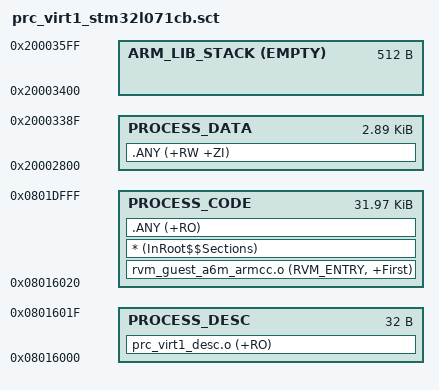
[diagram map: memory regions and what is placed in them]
;******************************************************************************
;Filename    : proc_virt1_stm32l071cb.sct
;Author      : The RVM project generator.
;Date        : 08/08/2024 16:25:18
;Licence     : Unlicense; see COPYING for details.
;Description : The scatter file for ARMv7-M layout. This file is intended
;              to be used with STM32L071CB.
;******************************************************************************

;Descriptor *******************************************************************
DESC 0x8016000 0x20
{
    ;Process header segment
    PROCESS_DESC 0x8016000 0x20
    {
        ;Process header
        prc_virt1_desc.o         (+RO)
    }
}
;End Descriptor ***************************************************************

;Process **********************************************************************
PROCESS 0x8016020 0x7FE0
{
    ;Process code segment
    PROCESS_CODE 0x8016020 0x7FE0
    {
        ;Entry point assembly
        rvm_guest_a6m_armcc.o     (RVM_ENTRY, +First)
        ;The lib code copying code
        *                      (InRoot$$Sections)
        ;The other code sections
        .ANY                   (+RO)
    }

    ;Process data segment
    PROCESS_DATA 0x20002800 0xB90
    {
        .ANY                   (+RW +ZI)
    }

    ;Process stack segment - required by armlib; reusing the booting thread's
    ARM_LIB_STACK 0x20003400 EMPTY 0x200
    {

    }
}
;End Process ******************************************************************

;End Of File ******************************************************************

;Copyright (C) Evo-Devo Instrum. All rights reserved **************************

